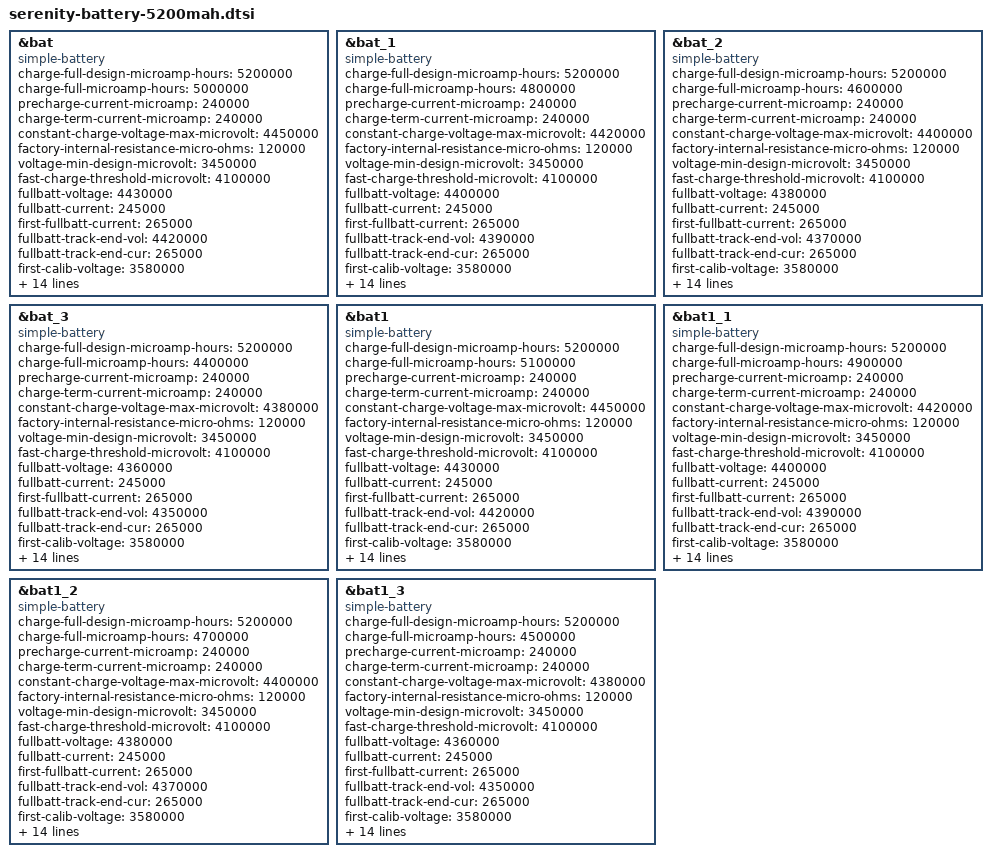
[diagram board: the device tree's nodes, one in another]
// SPDX-License-Identifier: GPL-2.0-only
/*
 * Serenity battery table - 5200mAh
 *
 * Xiaomi Redmi A5 / POCO C71 (serenity)
 * charge-full-design-microamp-hours = <5200000> (0x4F5880)
 */

&bat {
	compatible = "simple-battery";
	status = "okay";
	charge-full-design-microamp-hours = <5200000>;
	charge-full-microamp-hours = <5000000>;
	precharge-current-microamp = <240000>;
	charge-term-current-microamp = <240000>;
	constant-charge-voltage-max-microvolt = <4450000>;
	factory-internal-resistance-micro-ohms = <120000>;
	voltage-min-design-microvolt = <3450000>;
	fast-charge-threshold-microvolt = <4100000>;
	fullbatt-voltage = <4430000>;
	fullbatt-current = <245000>;
	first-fullbatt-current = <265000>;
	fullbatt-track-end-vol = <4420000>;
	fullbatt-track-end-cur = <265000>;
	first-calib-voltage = <3580000>;
	first-calib-capacity = <50>;
	ir-cv-offset-microvolt = <100000>;
	ir-rc-micro-ohms = <0>;
	ir-us-upper-limit-microvolt = <4500000>;
	ocv-capacity-celsius = <25>;
	ocv-capacity-table-0 = <4386000 100 4300000 95 4212000 90 4128000 85 4048000 80 3970000 75 3896000 70 3832000 65 3776000 60 3712000 55 3660000 50 3616000 45 3584000 40 3560000 35 3536000 30 3504000 25 3464000 20 3416000 15 3352000 10 3264000 5 3200000 0>;
	charge-sdp-current-microamp = <500000 500000>;
	charge-dcp-current-microamp = <2000000 1500000>;
	charge-cdp-current-microamp = <900000 900000>;
	charge-unknown-current-microamp = <1000000 1000000>;
	charge-fchg-current-microamp = <2000000 2000000>;
	charge-flash-current-microamp = <3000000 2000000>;
};

&bat_1 {
	compatible = "simple-battery";
	status = "okay";
	charge-full-design-microamp-hours = <5200000>;
	charge-full-microamp-hours = <4800000>;
	precharge-current-microamp = <240000>;
	charge-term-current-microamp = <240000>;
	constant-charge-voltage-max-microvolt = <4420000>;
	factory-internal-resistance-micro-ohms = <120000>;
	voltage-min-design-microvolt = <3450000>;
	fast-charge-threshold-microvolt = <4100000>;
	fullbatt-voltage = <4400000>;
	fullbatt-current = <245000>;
	first-fullbatt-current = <265000>;
	fullbatt-track-end-vol = <4390000>;
	fullbatt-track-end-cur = <265000>;
	first-calib-voltage = <3580000>;
	first-calib-capacity = <50>;
	ir-cv-offset-microvolt = <100000>;
	ir-rc-micro-ohms = <0>;
	ir-us-upper-limit-microvolt = <4500000>;
	ocv-capacity-celsius = <25>;
	ocv-capacity-table-0 = <4370000 100 4285000 95 4200000 90 4115000 85 4035000 80 3955000 75 3885000 70 3820000 65 3765000 60 3705000 55 3655000 50 3610000 45 3575000 40 3550000 35 3525000 30 3495000 25 3455000 20 3410000 15 3345000 10 3260000 5 3195000 0>;
	charge-sdp-current-microamp = <500000 500000>;
	charge-dcp-current-microamp = <2000000 1500000>;
	charge-cdp-current-microamp = <900000 900000>;
	charge-unknown-current-microamp = <1000000 1000000>;
	charge-fchg-current-microamp = <2000000 2000000>;
	charge-flash-current-microamp = <3000000 2000000>;
};

&bat_2 {
	compatible = "simple-battery";
	status = "okay";
	charge-full-design-microamp-hours = <5200000>;
	charge-full-microamp-hours = <4600000>;
	precharge-current-microamp = <240000>;
	charge-term-current-microamp = <240000>;
	constant-charge-voltage-max-microvolt = <4400000>;
	factory-internal-resistance-micro-ohms = <120000>;
	voltage-min-design-microvolt = <3450000>;
	fast-charge-threshold-microvolt = <4100000>;
	fullbatt-voltage = <4380000>;
	fullbatt-current = <245000>;
	first-fullbatt-current = <265000>;
	fullbatt-track-end-vol = <4370000>;
	fullbatt-track-end-cur = <265000>;
	first-calib-voltage = <3580000>;
	first-calib-capacity = <50>;
	ir-cv-offset-microvolt = <100000>;
	ir-rc-micro-ohms = <0>;
	ir-us-upper-limit-microvolt = <4500000>;
	ocv-capacity-celsius = <25>;
	ocv-capacity-table-0 = <4355000 100 4270000 95 4185000 90 4100000 85 4020000 80 3940000 75 3870000 70 3805000 65 3750000 60 3695000 55 3645000 50 3600000 45 3565000 40 3540000 35 3515000 30 3485000 25 3445000 20 3400000 15 3335000 10 3255000 5 3190000 0>;
	charge-sdp-current-microamp = <500000 500000>;
	charge-dcp-current-microamp = <2000000 1500000>;
	charge-cdp-current-microamp = <900000 900000>;
	charge-unknown-current-microamp = <1000000 1000000>;
	charge-fchg-current-microamp = <2000000 2000000>;
	charge-flash-current-microamp = <3000000 2000000>;
};

&bat_3 {
	compatible = "simple-battery";
	status = "okay";
	charge-full-design-microamp-hours = <5200000>;
	charge-full-microamp-hours = <4400000>;
	precharge-current-microamp = <240000>;
	charge-term-current-microamp = <240000>;
	constant-charge-voltage-max-microvolt = <4380000>;
	factory-internal-resistance-micro-ohms = <120000>;
	voltage-min-design-microvolt = <3450000>;
	fast-charge-threshold-microvolt = <4100000>;
	fullbatt-voltage = <4360000>;
	fullbatt-current = <245000>;
	first-fullbatt-current = <265000>;
	fullbatt-track-end-vol = <4350000>;
	fullbatt-track-end-cur = <265000>;
	first-calib-voltage = <3580000>;
	first-calib-capacity = <50>;
	ir-cv-offset-microvolt = <100000>;
	ir-rc-micro-ohms = <0>;
	ir-us-upper-limit-microvolt = <4500000>;
	ocv-capacity-celsius = <25>;
	ocv-capacity-table-0 = <4340000 100 4255000 95 4170000 90 4085000 85 4005000 80 3925000 75 3855000 70 3790000 65 3735000 60 3685000 55 3635000 50 3590000 45 3555000 40 3530000 35 3505000 30 3475000 25 3435000 20 3390000 15 3325000 10 3250000 5 3185000 0>;
	charge-sdp-current-microamp = <500000 500000>;
	charge-dcp-current-microamp = <2000000 1500000>;
	charge-cdp-current-microamp = <900000 900000>;
	charge-unknown-current-microamp = <1000000 1000000>;
	charge-fchg-current-microamp = <2000000 2000000>;
	charge-flash-current-microamp = <3000000 2000000>;
};

&bat1 {
	compatible = "simple-battery";
	status = "okay";
	charge-full-design-microamp-hours = <5200000>;
	charge-full-microamp-hours = <5100000>;
	precharge-current-microamp = <240000>;
	charge-term-current-microamp = <240000>;
	constant-charge-voltage-max-microvolt = <4450000>;
	factory-internal-resistance-micro-ohms = <120000>;
	voltage-min-design-microvolt = <3450000>;
	fast-charge-threshold-microvolt = <4100000>;
	fullbatt-voltage = <4430000>;
	fullbatt-current = <245000>;
	first-fullbatt-current = <265000>;
	fullbatt-track-end-vol = <4420000>;
	fullbatt-track-end-cur = <265000>;
	first-calib-voltage = <3580000>;
	first-calib-capacity = <50>;
	ir-cv-offset-microvolt = <100000>;
	ir-rc-micro-ohms = <0>;
	ir-us-upper-limit-microvolt = <4500000>;
	ocv-capacity-celsius = <25>;
	ocv-capacity-table-0 = <4386000 100 4300000 95 4212000 90 4128000 85 4048000 80 3970000 75 3896000 70 3832000 65 3776000 60 3712000 55 3660000 50 3616000 45 3584000 40 3560000 35 3536000 30 3504000 25 3464000 20 3416000 15 3352000 10 3264000 5 3200000 0>;
	charge-sdp-current-microamp = <500000 500000>;
	charge-dcp-current-microamp = <2000000 1500000>;
	charge-cdp-current-microamp = <900000 900000>;
	charge-unknown-current-microamp = <1000000 1000000>;
	charge-fchg-current-microamp = <2000000 2000000>;
	charge-flash-current-microamp = <3000000 2000000>;
};

&bat1_1 {
	compatible = "simple-battery";
	status = "okay";
	charge-full-design-microamp-hours = <5200000>;
	charge-full-microamp-hours = <4900000>;
	precharge-current-microamp = <240000>;
	charge-term-current-microamp = <240000>;
	constant-charge-voltage-max-microvolt = <4420000>;
	factory-internal-resistance-micro-ohms = <120000>;
	voltage-min-design-microvolt = <3450000>;
	fast-charge-threshold-microvolt = <4100000>;
	fullbatt-voltage = <4400000>;
	fullbatt-current = <245000>;
	first-fullbatt-current = <265000>;
	fullbatt-track-end-vol = <4390000>;
	fullbatt-track-end-cur = <265000>;
	first-calib-voltage = <3580000>;
	first-calib-capacity = <50>;
	ir-cv-offset-microvolt = <100000>;
	ir-rc-micro-ohms = <0>;
	ir-us-upper-limit-microvolt = <4500000>;
	ocv-capacity-celsius = <25>;
	ocv-capacity-table-0 = <4370000 100 4285000 95 4200000 90 4115000 85 4035000 80 3955000 75 3885000 70 3820000 65 3765000 60 3705000 55 3655000 50 3610000 45 3575000 40 3550000 35 3525000 30 3495000 25 3455000 20 3410000 15 3345000 10 3260000 5 3195000 0>;
	charge-sdp-current-microamp = <500000 500000>;
	charge-dcp-current-microamp = <2000000 1500000>;
	charge-cdp-current-microamp = <900000 900000>;
	charge-unknown-current-microamp = <1000000 1000000>;
	charge-fchg-current-microamp = <2000000 2000000>;
	charge-flash-current-microamp = <3000000 2000000>;
};

&bat1_2 {
	compatible = "simple-battery";
	status = "okay";
	charge-full-design-microamp-hours = <5200000>;
	charge-full-microamp-hours = <4700000>;
	precharge-current-microamp = <240000>;
	charge-term-current-microamp = <240000>;
	constant-charge-voltage-max-microvolt = <4400000>;
	factory-internal-resistance-micro-ohms = <120000>;
	voltage-min-design-microvolt = <3450000>;
	fast-charge-threshold-microvolt = <4100000>;
	fullbatt-voltage = <4380000>;
	fullbatt-current = <245000>;
	first-fullbatt-current = <265000>;
	fullbatt-track-end-vol = <4370000>;
	fullbatt-track-end-cur = <265000>;
	first-calib-voltage = <3580000>;
	first-calib-capacity = <50>;
	ir-cv-offset-microvolt = <100000>;
	ir-rc-micro-ohms = <0>;
	ir-us-upper-limit-microvolt = <4500000>;
	ocv-capacity-celsius = <25>;
	ocv-capacity-table-0 = <4355000 100 4270000 95 4185000 90 4100000 85 4020000 80 3940000 75 3870000 70 3805000 65 3750000 60 3695000 55 3645000 50 3600000 45 3565000 40 3540000 35 3515000 30 3485000 25 3445000 20 3400000 15 3335000 10 3255000 5 3190000 0>;
	charge-sdp-current-microamp = <500000 500000>;
	charge-dcp-current-microamp = <2000000 1500000>;
	charge-cdp-current-microamp = <900000 900000>;
	charge-unknown-current-microamp = <1000000 1000000>;
	charge-fchg-current-microamp = <2000000 2000000>;
	charge-flash-current-microamp = <3000000 2000000>;
};

&bat1_3 {
	compatible = "simple-battery";
	status = "okay";
	charge-full-design-microamp-hours = <5200000>;
	charge-full-microamp-hours = <4500000>;
	precharge-current-microamp = <240000>;
	charge-term-current-microamp = <240000>;
	constant-charge-voltage-max-microvolt = <4380000>;
	factory-internal-resistance-micro-ohms = <120000>;
	voltage-min-design-microvolt = <3450000>;
	fast-charge-threshold-microvolt = <4100000>;
	fullbatt-voltage = <4360000>;
	fullbatt-current = <245000>;
	first-fullbatt-current = <265000>;
	fullbatt-track-end-vol = <4350000>;
	fullbatt-track-end-cur = <265000>;
	first-calib-voltage = <3580000>;
	first-calib-capacity = <50>;
	ir-cv-offset-microvolt = <100000>;
	ir-rc-micro-ohms = <0>;
	ir-us-upper-limit-microvolt = <4500000>;
	ocv-capacity-celsius = <25>;
	ocv-capacity-table-0 = <4340000 100 4255000 95 4170000 90 4085000 85 4005000 80 3925000 75 3855000 70 3790000 65 3735000 60 3685000 55 3635000 50 3590000 45 3555000 40 3530000 35 3505000 30 3475000 25 3435000 20 3390000 15 3325000 10 3250000 5 3185000 0>;
	charge-sdp-current-microamp = <500000 500000>;
	charge-dcp-current-microamp = <2000000 1500000>;
	charge-cdp-current-microamp = <900000 900000>;
	charge-unknown-current-microamp = <1000000 1000000>;
	charge-fchg-current-microamp = <2000000 2000000>;
	charge-flash-current-microamp = <3000000 2000000>;
};
